# CTRL_MODULE_CORE register map
Vendor: Texas Instruments
Registers are 32-bit, access per field, reset 0x0 unless marked. A register's access mark holds for its fields unless they carry their own. Offsets are as the file gives them; [hi:lo] are bit positions; {n}, {i} and the like mark numbered series; 'fields as' and 'values as' point back to an identical list.

## CTRL_MODULE_CORE (part 4 of 12)
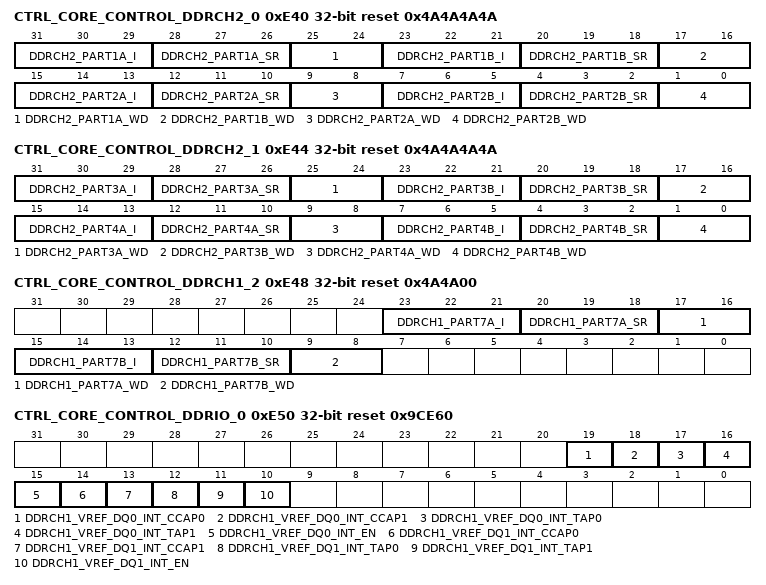
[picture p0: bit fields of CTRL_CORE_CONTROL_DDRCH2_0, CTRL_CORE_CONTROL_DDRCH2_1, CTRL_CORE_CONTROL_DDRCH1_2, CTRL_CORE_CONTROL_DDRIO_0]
0xE40 CTRL_CORE_CONTROL_DDRCH2_0 rw reset 0x4A4A4A4A — DDRCH2 control 0
  [31:29] DDRCH2_PART1A_I — PART1A Impedence control I[2:0] 0x0: Imp80 0x1: Imp60 0x2: Imp48 0x3: Imp40 0x4: Imp34 0x5: Reserved 0x6: Reserved 0x7: Reserved
  [28:26] DDRCH2_PART1A_SR — PART1A Slew Rate control SR[2:0]. All 8 values are valid. 0x0: Fastest .... 0x7: Slowest
  [25:24] DDRCH2_PART1A_WD — PART1A Weak driver control WD[1:0] -For single-ended operation: 0x0: Pull logic is disabled 0x1: Pull-up selected 0x2: Pull-down selected 0x3: Maintain the previous output value -For differential pair operation: 0x0: Pull logic is disabled 0x1: Pull-up selected for padp, pull-down selected for padn 0x2: Pull-down selected for padp, pull-up selected for padn 0x3: Maintain the previous output value
  [23:21] DDRCH2_PART1B_I — PART1B Impedence control I[2:0] 0x0: Imp80 0x1: Imp60 0x2: Imp48 0x3: Imp40 0x4: Imp34 0x5: Reserved 0x6: Reserved 0x7: Reserved
  [20:18] DDRCH2_PART1B_SR — PART1B Slew Rate control SR[2:0]. All 8 values are valid. 0x0: Fastest .... 0x7: Slowest
  [17:16] DDRCH2_PART1B_WD — PART1B Weak driver control WD[1:0] -For single-ended operation: 0x0: Pull logic is disabled 0x1: Pull-up selected 0x2: Pull-down selected 0x3: Maintain the previous output value -For differential pair operation: 0x0: Pull logic is disabled 0x1: Pull-up selected for padp, pull-down selected for padn 0x2: Pull-down selected for padp, pull-up selected for padn 0x3: Maintain the previous output value
  [15:13] DDRCH2_PART2A_I — PART2A Impedence control I[2:0] 0x0: Imp80 0x1: Imp60 0x2: Imp48 0x3: Imp40 0x4: Imp34 0x5: Reserved 0x6: Reserved 0x7: Reserved
  [12:10] DDRCH2_PART2A_SR — PART2A Slew Rate control SR[2:0]. All 8 values are valid. 0x0: Fastest .... 0x7: Slowest
  [9:8] DDRCH2_PART2A_WD — PART2A Weak driver control WD[1:0] -For single-ended operation: 0x0: Pull logic is disabled 0x1: Pull-up selected 0x2: Pull-down selected 0x3: Maintain the previous output value -For differential pair operation: 0x0: Pull logic is disabled 0x1: Pull-up selected for padp, pull-down selected for padn 0x2: Pull-down selected for padp, pull-up selected for padn 0x3: Maintain the previous output value
  [7:5] DDRCH2_PART2B_I — PART2B Impedence control I[2:0] 0x0: Imp80 0x1: Imp60 0x2: Imp48 0x3: Imp40 0x4: Imp34 0x5: Reserved 0x6: Reserved 0x7: Reserved
  [4:2] DDRCH2_PART2B_SR — PART2B Slew Rate control SR[2:0]. All 8 values are valid. 0x0: Fastest .... 0x7: Slowest
  [1:0] DDRCH2_PART2B_WD — PART2B Weak driver control WD[1:0] -For single-ended operation: 0x0: Pull logic is disabled 0x1: Pull-up selected 0x2: Pull-down selected 0x3: Maintain the previous output value -For differential pair operation: 0x0: Pull logic is disabled 0x1: Pull-up selected for padp, pull-down selected for padn 0x2: Pull-down selected for padp, pull-up selected for padn 0x3: Maintain the previous output value
0xE44 CTRL_CORE_CONTROL_DDRCH2_1 rw reset 0x4A4A4A4A — DDRCH2 control 1
  [31:29] DDRCH2_PART3A_I — PART3A Impedence control I[2:0] 0x0: Imp80 0x1: Imp60 0x2: Imp48 0x3: Imp40 0x4: Imp34 0x5: Reserved 0x6: Reserved 0x7: Reserved
  [28:26] DDRCH2_PART3A_SR — PART3A Slew Rate control SR[2:0]. All 8 values are valid. 0x0: Fastest .... 0x7: Slowest
  [25:24] DDRCH2_PART3A_WD — PART3A Weak driver control WD[1:0] -For single-ended operation: 0x0: Pull logic is disabled 0x1: Pull-up selected 0x2: Pull-down selected 0x3: Maintain the previous output value -For differential pair operation: 0x0: Pull logic is disabled 0x1: Pull-up selected for padp, pull-down selected for padn 0x2: Pull-down selected for padp, pull-up selected for padn 0x3: Maintain the previous output value
  [23:21] DDRCH2_PART3B_I — PART3B Impedence control I[2:0] 0x0: Imp80 0x1: Imp60 0x2: Imp48 0x3: Imp40 0x4: Imp34 0x5: Reserved 0x6: Reserved 0x7: Reserved
  [20:18] DDRCH2_PART3B_SR — PART3B Slew Rate control SR[2:0]. All 8 values are valid. 0x0: Fastest .... 0x7: Slowest
  [17:16] DDRCH2_PART3B_WD — PART3B Weak driver control WD[1:0] -For single-ended operation: 0x0: Pull logic is disabled 0x1: Pull-up selected 0x2: Pull-down selected 0x3: Maintain the previous output value -For differential pair operation: 0x0: Pull logic is disabled 0x1: Pull-up selected for padp, pull-down selected for padn 0x2: Pull-down selected for padp, pull-up selected for padn 0x3: Maintain the previous output value
  [15:13] DDRCH2_PART4A_I — PART4A Impedence control I[2:0] 0x0: Imp80 0x1: Imp60 0x2: Imp48 0x3: Imp40 0x4: Imp34 0x5: Reserved 0x6: Reserved 0x7: Reserved
  [12:10] DDRCH2_PART4A_SR — PART4A Slew Rate control SR[2:0]. All 8 values are valid. 0x0: Fastest .... 0x7: Slowest
  [9:8] DDRCH2_PART4A_WD — PART4A Weak driver control WD[1:0] -For single-ended operation: 0x0: Pull logic is disabled 0x1: Pull-up selected 0x2: Pull-down selected 0x3: Maintain the previous output value -For differential pair operation: 0x0: Pull logic is disabled 0x1: Pull-up selected for padp, pull-down selected for padn 0x2: Pull-down selected for padp, pull-up selected for padn 0x3: Maintain the previous output value
  [7:5] DDRCH2_PART4B_I — PART4B Impedence control I[2:0] 0x0: Imp80 0x1: Imp60 0x2: Imp48 0x3: Imp40 0x4: Imp34 0x5: Reserved 0x6: Reserved 0x7: Reserved
  [4:2] DDRCH2_PART4B_SR — PART4B Slew Rate control SR[2:0]. All 8 values are valid. 0x0: Fastest .... 0x7: Slowest
  [1:0] DDRCH2_PART4B_WD — PART4B Weak driver control WD[1:0] -For single-ended operation: 0x0: Pull logic is disabled 0x1: Pull-up selected 0x2: Pull-down selected 0x3: Maintain the previous output value -For differential pair operation: 0x0: Pull logic is disabled 0x1: Pull-up selected for padp, pull-down selected for padn 0x2: Pull-down selected for padp, pull-up selected for padn 0x3: Maintain the previous output value
0xE48 CTRL_CORE_CONTROL_DDRCH1_2 reset 0x4A4A00
  [23:21] DDRCH1_PART7A_I rw — PART7A Impedence control I[2:0] 0x0: Imp80 0x1: Imp60 0x2: Imp48 0x3: Imp40 0x4: Imp34 0x5: Reserved 0x6: Reserved 0x7: Reserved
  [20:18] DDRCH1_PART7A_SR rw — PART7A Slew Rate control SR[2:0]. All 8 values are valid. 0x0: Fastest .... 0x7: Slowest
  [17:16] DDRCH1_PART7A_WD rw — PART7A Weak driver control WD[1:0] -For single-ended operation: 0x0: Pull logic is disabled 0x1: Pull-up selected 0x2: Pull-down selected 0x3: Maintain the previous output value -For differential pair operation: 0x0: Pull logic is disabled 0x1: Pull-up selected for padp, pull-down selected for padn 0x2: Pull-down selected for padp, pull-up selected for padn 0x3: Maintain the previous output value
  [15:13] DDRCH1_PART7B_I rw — PART7B Impedence control I[2:0] 0x0: Imp80 0x1: Imp60 0x2: Imp48 0x3: Imp40 0x4: Imp34 0x5: Reserved 0x6: Reserved 0x7: Reserved
  [12:10] DDRCH1_PART7B_SR rw — PART7B Slew Rate control SR[2:0]. All 8 values are valid. 0x0: Fastest .... 0x7: Slowest
  [9:8] DDRCH1_PART7B_WD rw — PART7B Weak driver control WD[1:0] -For single-ended operation: 0x0: Pull logic is disabled 0x1: Pull-up selected 0x2: Pull-down selected 0x3: Maintain the previous output value -For differential pair operation: 0x0: Pull logic is disabled 0x1: Pull-up selected for padp, pull-down selected for padn 0x2: Pull-down selected for padp, pull-up selected for padn 0x3: Maintain the previous output value
0xE50 CTRL_CORE_CONTROL_DDRIO_0 reset 0x9CE60
  [all] fields
    0=DISABLE (Disabled); 1=ENABLE (Enabled)
  [19] DDRCH1_VREF_DQ0_INT_CCAP0 rw — Selection for coupling cap connection
  [18] DDRCH1_VREF_DQ0_INT_CCAP1 rw — Selection for coupling cap connection
  [17] DDRCH1_VREF_DQ0_INT_TAP0 rw — Selection for internal reference voltage drive
  [16] DDRCH1_VREF_DQ0_INT_TAP1 rw — Selection for internal reference voltage drive
  [15] DDRCH1_VREF_DQ0_INT_EN rw — Enable
  [14] DDRCH1_VREF_DQ1_INT_CCAP0 rw — Selection for coupling cap connection
  [13] DDRCH1_VREF_DQ1_INT_CCAP1 rw — Selection for coupling cap connection
  [12] DDRCH1_VREF_DQ1_INT_TAP0 rw — Selection for internal reference voltage drive
  [11] DDRCH1_VREF_DQ1_INT_TAP1 rw — Selection for internal reference voltage drive
  [10] DDRCH1_VREF_DQ1_INT_EN rw — Enable
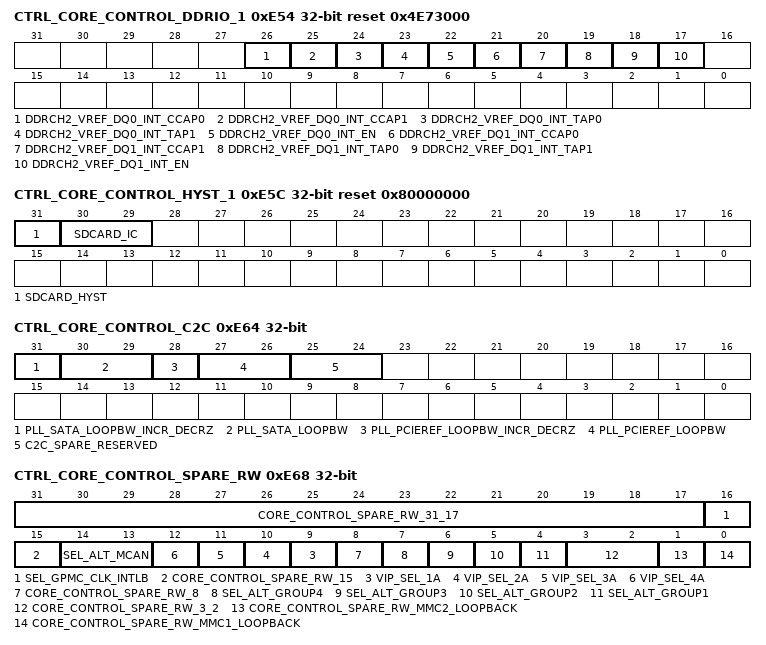
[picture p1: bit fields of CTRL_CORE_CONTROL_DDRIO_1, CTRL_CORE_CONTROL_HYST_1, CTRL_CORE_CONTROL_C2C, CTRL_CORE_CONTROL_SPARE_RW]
0xE54 CTRL_CORE_CONTROL_DDRIO_1 reset 0x4E73000
  [all] fields
    0=DISABLE (Disabled); 1=ENABLE (Enabled)
  [26] DDRCH2_VREF_DQ0_INT_CCAP0 rw — Selection for coupling cap connection
  [25] DDRCH2_VREF_DQ0_INT_CCAP1 rw — Selection for coupling cap connection
  [24] DDRCH2_VREF_DQ0_INT_TAP0 rw — Selection for internal reference voltage drive
  [23] DDRCH2_VREF_DQ0_INT_TAP1 rw — Selection for internal reference voltage drive
  [22] DDRCH2_VREF_DQ0_INT_EN rw — Enable
  [21] DDRCH2_VREF_DQ1_INT_CCAP0 rw — Selection for coupling cap connection
  [20] DDRCH2_VREF_DQ1_INT_CCAP1 rw — Selection for coupling cap connection
  [19] DDRCH2_VREF_DQ1_INT_TAP0 rw — Selection for internal reference voltage drive
  [18] DDRCH2_VREF_DQ1_INT_TAP1 rw — Selection for internal reference voltage drive
  [17] DDRCH2_VREF_DQ1_INT_EN rw — Enable
0xE5C CTRL_CORE_CONTROL_HYST_1 reset 0x80000000 — Register for hysteresis and impedance control of the MMC1 pads. Effective when corresponding MUXMODE field is not configured for MMC operation.
  [31] SDCARD_HYST rw — Hysteresis control for sdcard 0x0 = Disabled 0x1 = Enabled
  [30:29] SDCARD_IC rw — Drive strength control for MMC1 pads In 3.3V signaling mode: 0x0: 50 Ohms Drive Strength 0x1: 33 Ohms Drive Strength 0x2: 66 Ohms Drive Strength 0x3: Reserved In 1.8V signaling mode: 0x0: 44 Ohms Drive Strength 0x1: 33 Ohms Drive Strength 0x2: 58 Ohms Drive Strength 0x3: 100 Ohms Drive Strength
0xE64 CTRL_CORE_CONTROL_C2C — Loop Bandwidth control for DPLL_SATA and DPLL_PCIE_REF.
  [31] PLL_SATA_LOOPBW_INCR_DECRZ rw — 0x0: Decrease DPLL_SATA loop bandwidth 0x1: Increase DPLL_SATA loop bandwidth
  [30:29] PLL_SATA_LOOPBW rw — DPLL_SATA loop bandwidth mode If PLL_SATA_LOOPBW_INCR_DECRZ = 0x0: 0x0: 1x Mode (Loop BW is REF_CLK/50) 0x1: 0.5x Mode (Loop BW is REF_CLK/100) 0x2: 0.25x Mode (Loop BW is REF_CLK/200) 0x3: 0.125x Mode (Loop BW is REF_CLK/400) If PLL_SATA_LOOPBW_INCR_DECRZ = 0x1: 0x0: 1x Mode (Loop BW is REF_CLK/50) 0x1: 2x Mode (Loop BW is REF_CLK/25) 0x2: Reserved 0x3: Reserved
  [28] PLL_PCIEREF_LOOPBW_INCR_DECRZ rw — 0x0: Decrease DPLL_PCIE_REF loop bandwidth 0x1: Increase DPLL_PCIE_REF loop bandwidth
  [27:26] PLL_PCIEREF_LOOPBW rw — DPLL_PCIE_REF loop bandwidth mode If PLL_PCIEREF_LOOPBW_INCR_DECRZ = 0x0: 0x0: 1x Mode (Loop BW is REF_CLK/50) 0x1: 0.5x Mode (Loop BW is REF_CLK/100) 0x2: 0.25x Mode (Loop BW is REF_CLK/200) 0x3: 0.125x Mode (Loop BW is REF_CLK/400) If PLL_PCIEREF_LOOPBW_INCR_DECRZ = 0x1: 0x0: 1x Mode (Loop BW is REF_CLK/50) 0x1: 2x Mode (Loop BW is REF_CLK/25) 0x2: Reserved 0x3: Reserved
  [25:24] C2C_SPARE_RESERVED rw — Reserved bits
0xE68 CTRL_CORE_CONTROL_SPARE_RW rw
  [31:17] CORE_CONTROL_SPARE_RW_31_17 — Spare bits
  [16] SEL_GPMC_CLK_INTLB — Selects the source of loopback clock for gpmc_clk. 0x0: Loopback clock from the I/O pad is selected 0x1: Internal loopback clock is selected
  [15] CORE_CONTROL_SPARE_RW_15 — Spare bits
  [14:13] SEL_ALT_MCAN — Selection for MCAN signal muxing 0x0: The dcan2_tx and dcan2_rx signals are on the gpio6_14 and gpio6_15 pads when MUXMODE = 0x2 or the dcan1_tx and dcan1_rx signals are on the dcan1_tx and dcan1_rx pads when MUXMODE = 0x0. 0x1: The mcan_tx and mcan_rx signals are on the dcan1_tx and dcan1_rx pads when MUXMODE = 0x0. 0x2: The mcan_tx and mcan_rx signals are on the gpio6_14 and gpio6_15 pads when MUXMODE = 0x2. 0x3: Reserved
  [n+8] VIP_SEL_{n}A (n=1..4) — 0x0: Input for vin{n}a comes from device vin{n}a pads 0x1: Input for vin{n}a comes from CAL video port {n} signals
  [8] CORE_CONTROL_SPARE_RW_8 — Spare bit
  [7] SEL_ALT_GROUP4 — Selects a signal as described in
  [6] SEL_ALT_GROUP3 — 0x0: GPIO function is selected on the pads from GROUP3 0x1: New function is selected on the pads from GROUP3 as described in
  [5] SEL_ALT_GROUP2 — Selects a signal as described in
  [4] SEL_ALT_GROUP1 — 0x0: GPIO function is selected on the pads from GROUP1 0x1: New function is selected on the pads from GROUP1 as described in
  [3:2] CORE_CONTROL_SPARE_RW_3_2 — Spare bits
  [1] CORE_CONTROL_SPARE_RW_MMC2_LOOPBACK — Selects the source of loopback clock for mmc2_clk. 0x0: Loopback clock from the I/O pad is selected 0x1: Internal loopback clock is selected
  [0] CORE_CONTROL_SPARE_RW_MMC1_LOOPBACK — Selects the source of loopback clock for mmc1_clk. 0x0: Loopback clock from the I/O pad is selected 0x1: Internal loopback clock is selected
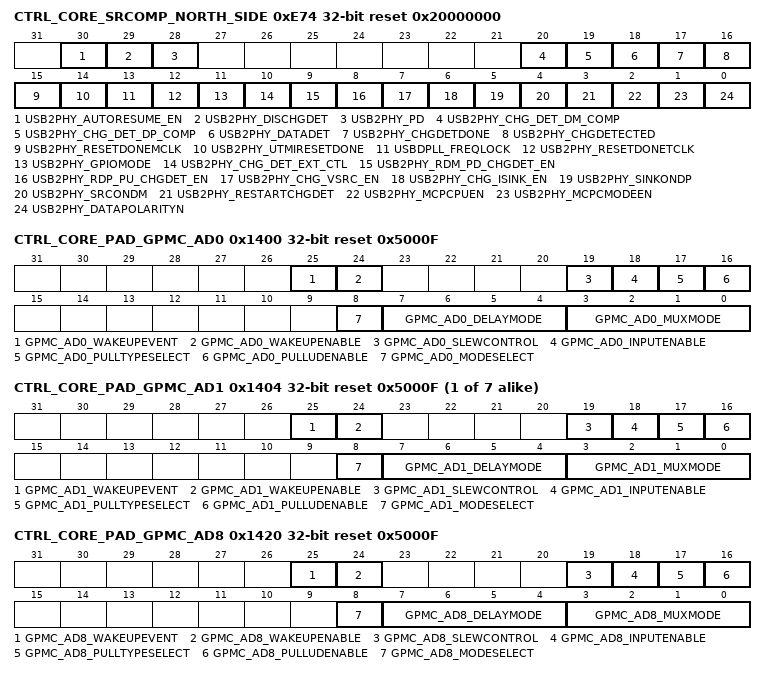
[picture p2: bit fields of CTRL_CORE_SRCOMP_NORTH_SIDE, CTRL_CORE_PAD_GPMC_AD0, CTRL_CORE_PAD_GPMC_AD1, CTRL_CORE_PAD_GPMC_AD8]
0xE74 CTRL_CORE_SRCOMP_NORTH_SIDE reset 0x20000000 — This register is related to the USB2_PHY2.
  [30] USB2PHY_AUTORESUME_EN rw — Auto resume enable 0x0: disable autoresume 0x1: enable autoresume
  [29] USB2PHY_DISCHGDET rw — Disable charger detect 0x0: charger detect function enabled 0x1: charger detect function disabled
  [28] USB2PHY_PD rw — Power down the entire USB2_PHY2 (data, common module and UTMI). 0x0: Normal operation 0x1: Power down the USB2_PHY2
  [20] USB2PHY_CHG_DET_DM_COMP ro — Output of the comparator on DM during the resistor host detect protocol 0x0: DM line is below 0.75V to 0.95V 0x1: DM line is above 0.75V to 0.95V
  [19] USB2PHY_CHG_DET_DP_COMP ro — Output of the comparator on DP during the resistor host detect protocol 0x0: DP line is below 0.75V to 0.95V 0x1: DP line is above 0.75V to 0.95V
  [18] USB2PHY_DATADET ro — Output of the charger detect comparator 0x0: DM line is below 0.25V to 0.4V 0x1: DM line is above 0.25V to 0.4V
  [17] USB2PHY_CHGDETDONE ro — Status indicates that charger detection protocol is over 0x0: charger detection protocol is not over 0x1: charger detection protocol is over
  [16] USB2PHY_CHGDETECTED ro — Output of the charger detection protocol 0x0: charger not detected 0x1: charger detected
  [15] USB2PHY_RESETDONEMCLK ro — OCP reset status 0x0: OCP domain is in reset 0x1: OCP domain is out of reset
  [14] USB2PHY_UTMIRESETDONE ro — UTMI FSM reset status 0x0: UTMI FSMs are in reset 0x1: UTMI FSMs are out of reset
  [13] USBDPLL_FREQLOCK ro — Status from USB DPLL
  [12] USB2PHY_RESETDONETCLK ro — resetdonetclk status from USB2_PHY2
  [11] USB2PHY_GPIOMODE rw — GPIO mode 0x0: USB mode enabled 0x1: GPIO mode enabled
  [10] USB2PHY_CHG_DET_EXT_CTL rw — Charge detect external control 0x0: charger detect internal state machine used 0x1: charge detect statemachine is bypassed
  [9] USB2PHY_RDM_PD_CHGDET_EN rw — DM Pull down control 0x0: PD disabled 0x1: PD enabled
  [8] USB2PHY_RDP_PU_CHGDET_EN rw — DP Pull up control 0x0: PU disabled 0x1: PU enabled
  [7] USB2PHY_CHG_VSRC_EN rw — VSRC enable on DP line: Host charger case 0x0: disable VSRC drive on DP 0x1: drives VSRC 600mV on DP line
  [6] USB2PHY_CHG_ISINK_EN rw — ISINK enable on DM line: Host charger case 0x0: disable the ISINK on DM 0x1: enables the ISINK (100uA) on DM line
  [5] USB2PHY_SINKONDP rw — When '1' current sink is connected to DP instead of DM 0x0: Default value 0x1: enables the ISINK on DP instead of DM
  [4] USB2PHY_SRCONDM rw — When '1' voltage source is connected to DP instead of DM 0x0: Default value 0x1: enable the VSRC on DM instead of DP
  [3] USB2PHY_RESTARTCHGDET rw — restartchgdet: '1' for 1 msec cause the CD_START to reset 0x0: Default value 0x1: a high pulse of 1 msec causes the charger detect to restart on negative edge of restartchgdet
  [2] USB2PHY_MCPCPUEN rw — MCPC Pull up enable 0x0: disable the MCPC pull up 0x1: enable the 4.7K to10K pull up on receive line DP when datapolarityn is 0 and DM when datapolarityn is 1
  [1] USB2PHY_MCPCMODEEN rw — MCPC Mode enable 0x0: disable MCPC mode 0x1: enable MCPC mode
  [0] USB2PHY_DATAPOLARITYN rw — Data polarity 0x0: DP functionality is on DP and DM funcationality is on DM 0x1: DP functionality is on DM and DM functionality is on DP
0xE78 CTRL_CORE_SRCOMP_SOUTH_SIDE ro — This register is related to the USB2_PHY2.
  [14:12] USB2PHY_CHG_DET_STATUS — Status of charger detection 0x0: Wait state 0x1: No contact 0x2: PS/2 0x3: Unknown error 0x4: Dedicated charger 0x5: HOST charger 0x6: PC 0x7: Interrupt
0x1400 CTRL_CORE_PAD_GPMC_AD0 reset 0x5000F
  [25] GPMC_AD0_WAKEUPEVENT ro
    0=NOWAKEUP (No wakeup event detected); 1=WAKEUP (Wakeup event detected)
  [24] GPMC_AD0_WAKEUPENABLE rw
    0=DISABLE (Wakeup is disabled); 1=ENABLE (Wakeup is enabled)
  [19] GPMC_AD0_SLEWCONTROL rw
    0=FAST_SLEW (Fast slew is selected); 1=SLOW_SLEW (Slow slew is selected)
  [18] GPMC_AD0_INPUTENABLE rw
    0=DISABLE (Receive mode is disabled); 1=ENABLE (Receive mode is enabled)
  [17] GPMC_AD0_PULLTYPESELECT rw
    0=PULL_DOWN (Pull Down is selected); 1=PULL_UP (Pull Up is selected)
  [16] GPMC_AD0_PULLUDENABLE rw
    0=ENABLE (Enables weak Pull Up/Down); 1=DISABLE (Disables weak Pull Up/Down)
  [8] GPMC_AD0_MODESELECT rw — Selects between the Default IO Timing Mode and a Virtual or Manual IO Timing Mode.Refer to the device Data Manual for definition of the required settings for a given mode of operation. When this bit is 0b1, a Virtual IO Timing Mode can be selected via the DELAYMODE field of this register, as described in , Virtual IO Timing Modes. Manual IO Timing Modes are selected via the procedure described in , Manual IO Timing Modes.
    0=MUX_MODE (Default IO Timing Mode is used); 1=DELAY_MODE (A Virtual or Manual IO Timing Mode is used)
  [7:4] GPMC_AD0_DELAYMODE rw — This bit field selects the Virtual Timing Mode used when the MODESELECT bit is set to 0b1. See, Virtual IO Timing Modes for details.
  [3:0] GPMC_AD0_MUXMODE rw
    0=GPMC_AD0; 2=VIN3A_D0; 3=VOUT3_D0; 14=GPIO1_6; 15=SYSBOOT0
{0x1400+4i} CTRL_CORE_PAD_GPMC_AD{i} reset 0x5000F (i=1..7)
  [25] GPMC_AD{i}_WAKEUPEVENT ro
    values as CTRL_CORE_PAD_GPMC_AD0.GPMC_AD0_WAKEUPEVENT
  [24] GPMC_AD{i}_WAKEUPENABLE rw
    0=DISABLE (Wakeup is disabled); 1=ENABLE (Wakeup is enabled)
  [19] GPMC_AD{i}_SLEWCONTROL rw
    values as CTRL_CORE_PAD_GPMC_AD0.GPMC_AD0_SLEWCONTROL
  [18] GPMC_AD{i}_INPUTENABLE rw
    values as CTRL_CORE_PAD_GPMC_AD0.GPMC_AD0_INPUTENABLE
  [17] GPMC_AD{i}_PULLTYPESELECT rw
    values as CTRL_CORE_PAD_GPMC_AD0.GPMC_AD0_PULLTYPESELECT
  [16] GPMC_AD{i}_PULLUDENABLE rw
    values as CTRL_CORE_PAD_GPMC_AD0.GPMC_AD0_PULLUDENABLE
  [8] GPMC_AD{i}_MODESELECT rw — Selects between the Default IO Timing Mode and a Virtual or Manual IO Timing Mode. Refer to the device Data Manual for definition of the required settings for a given mode of operation. When this bit is 0b1, a Virtual IO Timing Mode can be selected via the DELAYMODE field of this register, as described in, Virtual IO Timing Modes. Manual IO Timing Modes are selected via the procedure described in , Manual IO Timing Modes.
    values as CTRL_CORE_PAD_GPMC_AD0.GPMC_AD0_MODESELECT
  [7:4] GPMC_AD{i}_DELAYMODE rw — This bit field selects the Virtual Timing Mode used when the MODESELECT bit is set to 0b1. See, Virtual IO Timing Modes for details.
  [3:0] GPMC_AD{i}_MUXMODE rw
    0=GPMC_AD{i}; 2=VIN3A_D{i}; 3=VOUT3_D{i}; 14=GPIO1_{i+6}; 15=SYSBOOT{i}
0x1420 CTRL_CORE_PAD_GPMC_AD8 reset 0x5000F
  [25] GPMC_AD8_WAKEUPEVENT ro
    values as CTRL_CORE_PAD_GPMC_AD0.GPMC_AD0_WAKEUPEVENT
  [24] GPMC_AD8_WAKEUPENABLE rw
    0=DISABLE (Wakeup is disabled); 1=ENABLE (Wakeup is enabled)
  [19] GPMC_AD8_SLEWCONTROL rw
    values as CTRL_CORE_PAD_GPMC_AD0.GPMC_AD0_SLEWCONTROL
  [18] GPMC_AD8_INPUTENABLE rw
    values as CTRL_CORE_PAD_GPMC_AD0.GPMC_AD0_INPUTENABLE
  [17] GPMC_AD8_PULLTYPESELECT rw
    values as CTRL_CORE_PAD_GPMC_AD0.GPMC_AD0_PULLTYPESELECT
  [16] GPMC_AD8_PULLUDENABLE rw
    values as CTRL_CORE_PAD_GPMC_AD0.GPMC_AD0_PULLUDENABLE
  [8] GPMC_AD8_MODESELECT rw — Selects between the Default IO Timing Mode and a Virtual or Manual IO Timing Mode. Refer to the device Data Manual for definition of the required settings for a given mode of operation. When this bit is 0b1, a Virtual IO Timing Mode can be selected via the DELAYMODE field of this register, as described in, Virtual IO Timing Modes. Manual IO Timing Modes are selected via the procedure described in , Manual IO Timing Modes.
    values as CTRL_CORE_PAD_GPMC_AD0.GPMC_AD0_MODESELECT
  [7:4] GPMC_AD8_DELAYMODE rw — This bit field selects the Virtual Timing Mode used when the MODESELECT bit is set to 0b1. See, Virtual IO Timing Modes for details.
  [3:0] GPMC_AD8_MUXMODE rw
    0=GPMC_AD8; 2=VIN3A_D8; 3=VOUT3_D8; 14=GPIO7_18; 15=SYSBOOT8
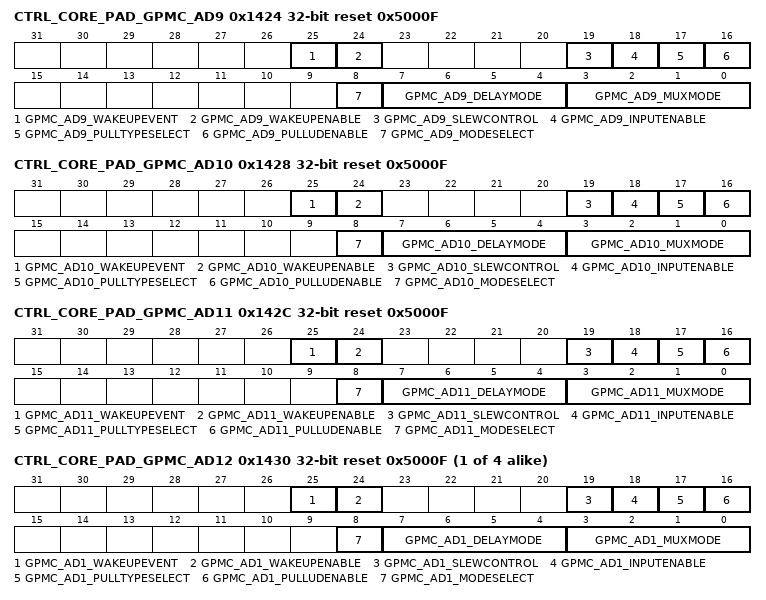
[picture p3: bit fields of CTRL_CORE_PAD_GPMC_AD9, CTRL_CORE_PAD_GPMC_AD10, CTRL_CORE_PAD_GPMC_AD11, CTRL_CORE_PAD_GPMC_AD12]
0x1424 CTRL_CORE_PAD_GPMC_AD9 reset 0x5000F
  [25] GPMC_AD9_WAKEUPEVENT ro
    values as CTRL_CORE_PAD_GPMC_AD0.GPMC_AD0_WAKEUPEVENT
  [24] GPMC_AD9_WAKEUPENABLE rw
    0=DISABLE (Wakeup is disabled); 1=ENABLE (Wakeup is enabled)
  [19] GPMC_AD9_SLEWCONTROL rw
    values as CTRL_CORE_PAD_GPMC_AD0.GPMC_AD0_SLEWCONTROL
  [18] GPMC_AD9_INPUTENABLE rw
    values as CTRL_CORE_PAD_GPMC_AD0.GPMC_AD0_INPUTENABLE
  [17] GPMC_AD9_PULLTYPESELECT rw
    values as CTRL_CORE_PAD_GPMC_AD0.GPMC_AD0_PULLTYPESELECT
  [16] GPMC_AD9_PULLUDENABLE rw
    values as CTRL_CORE_PAD_GPMC_AD0.GPMC_AD0_PULLUDENABLE
  [8] GPMC_AD9_MODESELECT rw — Selects between the Default IO Timing Mode and a Virtual or Manual IO Timing Mode. Refer to the device Data Manual for definition of the required settings for a given mode of operation. When this bit is 0b1, a Virtual IO Timing Mode can be selected via the DELAYMODE field of this register, as described in, Virtual IO Timing Modes. Manual IO Timing Modes are selected via the procedure described in , Manual IO Timing Modes.
    values as CTRL_CORE_PAD_GPMC_AD0.GPMC_AD0_MODESELECT
  [7:4] GPMC_AD9_DELAYMODE rw — This bit field selects the Virtual Timing Mode used when the MODESELECT bit is set to 0b1. See, Virtual IO Timing Modes for details.
  [3:0] GPMC_AD9_MUXMODE rw
    0=GPMC_AD9; 2=VIN3A_D9; 3=VOUT3_D9; 14=GPIO7_19; 15=SYSBOOT9
0x1428 CTRL_CORE_PAD_GPMC_AD10 reset 0x5000F
  [25] GPMC_AD10_WAKEUPEVENT ro
    values as CTRL_CORE_PAD_GPMC_AD0.GPMC_AD0_WAKEUPEVENT
  [24] GPMC_AD10_WAKEUPENABLE rw
    0=DISABLE (Wakeup is disabled); 1=ENABLE (Wakeup is enabled)
  [19] GPMC_AD10_SLEWCONTROL rw
    values as CTRL_CORE_PAD_GPMC_AD0.GPMC_AD0_SLEWCONTROL
  [18] GPMC_AD10_INPUTENABLE rw
    values as CTRL_CORE_PAD_GPMC_AD0.GPMC_AD0_INPUTENABLE
  [17] GPMC_AD10_PULLTYPESELECT rw
    values as CTRL_CORE_PAD_GPMC_AD0.GPMC_AD0_PULLTYPESELECT
  [16] GPMC_AD10_PULLUDENABLE rw
    values as CTRL_CORE_PAD_GPMC_AD0.GPMC_AD0_PULLUDENABLE
  [8] GPMC_AD10_MODESELECT rw — Selects between the Default IO Timing Mode and a Virtual or Manual IO Timing Mode. Refer to the device Data Manual for definition of the required settings for a given mode of operation. When this bit is 0b1, a Virtual IO Timing Mode can be selected via the DELAYMODE field of this register, as described in, Virtual IO Timing Modes. Manual IO Timing Modes are selected via the procedure described in , Manual IO Timing Modes.
    values as CTRL_CORE_PAD_GPMC_AD0.GPMC_AD0_MODESELECT
  [7:4] GPMC_AD10_DELAYMODE rw — This bit field selects the Virtual Timing Mode used when the MODESELECT bit is set to 0b1. See, Virtual IO Timing Modes for details.
  [3:0] GPMC_AD10_MUXMODE rw
    0=GPMC_AD10; 2=VIN3A_D10; 3=VOUT3_D10; 14=GPIO7_28; 15=SYSBOOT10
0x142C CTRL_CORE_PAD_GPMC_AD11 reset 0x5000F
  [25] GPMC_AD11_WAKEUPEVENT ro
    values as CTRL_CORE_PAD_GPMC_AD0.GPMC_AD0_WAKEUPEVENT
  [24] GPMC_AD11_WAKEUPENABLE rw
    0=DISABLE (Wakeup is disabled); 1=ENABLE (Wakeup is enabled)
  [19] GPMC_AD11_SLEWCONTROL rw
    values as CTRL_CORE_PAD_GPMC_AD0.GPMC_AD0_SLEWCONTROL
  [18] GPMC_AD11_INPUTENABLE rw
    values as CTRL_CORE_PAD_GPMC_AD0.GPMC_AD0_INPUTENABLE
  [17] GPMC_AD11_PULLTYPESELECT rw
    values as CTRL_CORE_PAD_GPMC_AD0.GPMC_AD0_PULLTYPESELECT
  [16] GPMC_AD11_PULLUDENABLE rw
    values as CTRL_CORE_PAD_GPMC_AD0.GPMC_AD0_PULLUDENABLE
  [8] GPMC_AD11_MODESELECT rw — Selects between the Default IO Timing Mode and a Virtual or Manual IO Timing Mode. Refer to the device Data Manual for definition of the required settings for a given mode of operation. When this bit is 0b1, a Virtual IO Timing Mode can be selected via the DELAYMODE field of this register, as described in, Virtual IO Timing Modes. Manual IO Timing Modes are selected via the procedure described in , Manual IO Timing Modes.
    values as CTRL_CORE_PAD_GPMC_AD0.GPMC_AD0_MODESELECT
  [7:4] GPMC_AD11_DELAYMODE rw — This bit field selects the Virtual Timing Mode used when the MODESELECT bit is set to 0b1. See, Virtual IO Timing Modes for details.
  [3:0] GPMC_AD11_MUXMODE rw
    0=GPMC_AD11; 2=VIN3A_D11; 3=VOUT3_D11; 14=GPIO7_29; 15=SYSBOOT11
{0x1400+4i} CTRL_CORE_PAD_GPMC_AD{i} reset 0x5000F (i=12..15)
  fields as CTRL_CORE_PAD_GPMC_AD1
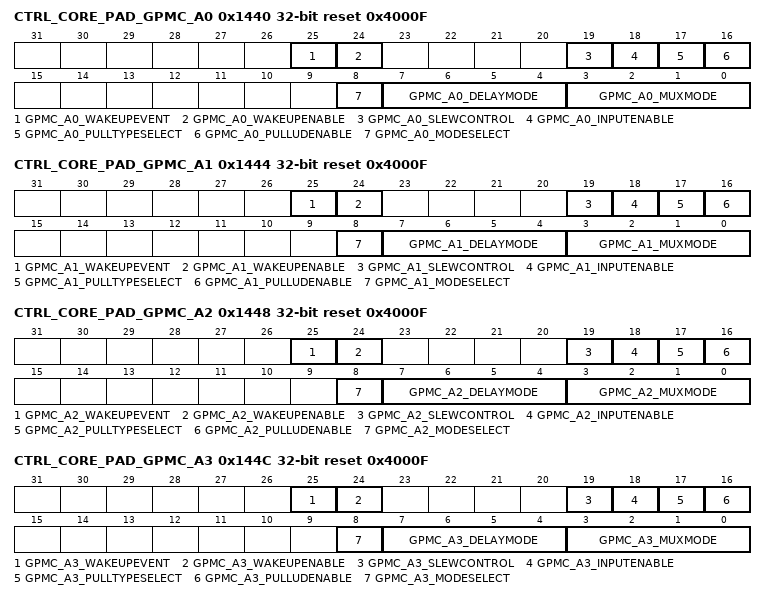
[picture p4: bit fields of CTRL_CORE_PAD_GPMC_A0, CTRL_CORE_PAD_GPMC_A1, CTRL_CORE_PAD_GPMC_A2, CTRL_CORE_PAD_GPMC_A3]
0x1440 CTRL_CORE_PAD_GPMC_A0 reset 0x4000F
  [25] GPMC_A0_WAKEUPEVENT ro
    values as CTRL_CORE_PAD_GPMC_AD0.GPMC_AD0_WAKEUPEVENT
  [24] GPMC_A0_WAKEUPENABLE rw
    0=DISABLE (Wakeup is disabled); 1=ENABLE (Wakeup is enabled)
  [19] GPMC_A0_SLEWCONTROL rw
    values as CTRL_CORE_PAD_GPMC_AD0.GPMC_AD0_SLEWCONTROL
  [18] GPMC_A0_INPUTENABLE rw
    values as CTRL_CORE_PAD_GPMC_AD0.GPMC_AD0_INPUTENABLE
  [17] GPMC_A0_PULLTYPESELECT rw
    values as CTRL_CORE_PAD_GPMC_AD0.GPMC_AD0_PULLTYPESELECT
  [16] GPMC_A0_PULLUDENABLE rw
    values as CTRL_CORE_PAD_GPMC_AD0.GPMC_AD0_PULLUDENABLE
  [8] GPMC_A0_MODESELECT rw — Selects between the Default IO Timing Mode and a Virtual or Manual IO Timing Mode. Refer to the device Data Manual for definition of the required settings for a given mode of operation. When this bit is 0b1, a Virtual IO Timing Mode can be selected via the DELAYMODE field of this register, as described in, Virtual IO Timing Modes. Manual IO Timing Modes are selected via the procedure described in , Manual IO Timing Modes.
    values as CTRL_CORE_PAD_GPMC_AD0.GPMC_AD0_MODESELECT
  [7:4] GPMC_A0_DELAYMODE rw — This bit field selects the Virtual Timing Mode used when the MODESELECT bit is set to 0b1. See, Virtual IO Timing Modes for details.
  [3:0] GPMC_A0_MUXMODE rw
    0=GPMC_A0; 2=VIN3A_D16; 3=VOUT3_D16; 4=VIN4A_D0; 6=VIN4B_D0; 7=I2C4_SCL; 8=UART5_RXD; 14=GPIO7_3; 15=DRIVER OFF
0x1444 CTRL_CORE_PAD_GPMC_A1 reset 0x4000F
  [25] GPMC_A1_WAKEUPEVENT ro
    values as CTRL_CORE_PAD_GPMC_AD0.GPMC_AD0_WAKEUPEVENT
  [24] GPMC_A1_WAKEUPENABLE rw
    0=DISABLE (Wakeup is disabled); 1=ENABLE (Wakeup is enabled)
  [19] GPMC_A1_SLEWCONTROL rw
    values as CTRL_CORE_PAD_GPMC_AD0.GPMC_AD0_SLEWCONTROL
  [18] GPMC_A1_INPUTENABLE rw
    values as CTRL_CORE_PAD_GPMC_AD0.GPMC_AD0_INPUTENABLE
  [17] GPMC_A1_PULLTYPESELECT rw
    values as CTRL_CORE_PAD_GPMC_AD0.GPMC_AD0_PULLTYPESELECT
  [16] GPMC_A1_PULLUDENABLE rw
    values as CTRL_CORE_PAD_GPMC_AD0.GPMC_AD0_PULLUDENABLE
  [8] GPMC_A1_MODESELECT rw — Selects between the Default IO Timing Mode and a Virtual or Manual IO Timing Mode. Refer to the device Data Manual for definition of the required settings for a given mode of operation. When this bit is 0b1, a Virtual IO Timing Mode can be selected via the DELAYMODE field of this register, as described in, Virtual IO Timing Modes. Manual IO Timing Modes are selected via the procedure described in , Manual IO Timing Modes.
    values as CTRL_CORE_PAD_GPMC_AD0.GPMC_AD0_MODESELECT
  [7:4] GPMC_A1_DELAYMODE rw — This bit field selects the Virtual Timing Mode used when the MODESELECT bit is set to 0b1. See, Virtual IO Timing Modes for details.
  [3:0] GPMC_A1_MUXMODE rw
    0=GPMC_A1; 2=VIN3A_D17; 3=VOUT3_D17; 4=VIN4A_D1; 6=VIN4B_D1; 7=I2C4_SDA; 8=UART5_TXD; 14=GPIO7_4; 15=DRIVER OFF
0x1448 CTRL_CORE_PAD_GPMC_A2 reset 0x4000F
  [25] GPMC_A2_WAKEUPEVENT ro
    values as CTRL_CORE_PAD_GPMC_AD0.GPMC_AD0_WAKEUPEVENT
  [24] GPMC_A2_WAKEUPENABLE rw
    0=DISABLE (Wakeup is disabled); 1=ENABLE (Wakeup is enabled)
  [19] GPMC_A2_SLEWCONTROL rw
    values as CTRL_CORE_PAD_GPMC_AD0.GPMC_AD0_SLEWCONTROL
  [18] GPMC_A2_INPUTENABLE rw
    values as CTRL_CORE_PAD_GPMC_AD0.GPMC_AD0_INPUTENABLE
  [17] GPMC_A2_PULLTYPESELECT rw
    values as CTRL_CORE_PAD_GPMC_AD0.GPMC_AD0_PULLTYPESELECT
  [16] GPMC_A2_PULLUDENABLE rw
    values as CTRL_CORE_PAD_GPMC_AD0.GPMC_AD0_PULLUDENABLE
  [8] GPMC_A2_MODESELECT rw — Selects between the Default IO Timing Mode and a Virtual or Manual IO Timing Mode. Refer to the device Data Manual for definition of the required settings for a given mode of operation. When this bit is 0b1, a Virtual IO Timing Mode can be selected via the DELAYMODE field of this register, as described in, Virtual IO Timing Modes. Manual IO Timing Modes are selected via the procedure described in , Manual IO Timing Modes.
    values as CTRL_CORE_PAD_GPMC_AD0.GPMC_AD0_MODESELECT
  [7:4] GPMC_A2_DELAYMODE rw — This bit field selects the Virtual Timing Mode used when the MODESELECT bit is set to 0b1. See, Virtual IO Timing Modes for details.
  [3:0] GPMC_A2_MUXMODE rw
    0=GPMC_A2; 2=VIN3A_D18; 3=VOUT3_D18; 4=VIN4A_D2; 6=VIN4B_D2; 7=UART7_RXD; 8=UART5_CTSN; 14=GPIO7_5; 15=DRIVER OFF
0x144C CTRL_CORE_PAD_GPMC_A3 reset 0x4000F
  [25] GPMC_A3_WAKEUPEVENT ro
    values as CTRL_CORE_PAD_GPMC_AD0.GPMC_AD0_WAKEUPEVENT
  [24] GPMC_A3_WAKEUPENABLE rw
    0=DISABLE (Wakeup is disabled); 1=ENABLE (Wakeup is enabled)
  [19] GPMC_A3_SLEWCONTROL rw
    values as CTRL_CORE_PAD_GPMC_AD0.GPMC_AD0_SLEWCONTROL
  [18] GPMC_A3_INPUTENABLE rw
    values as CTRL_CORE_PAD_GPMC_AD0.GPMC_AD0_INPUTENABLE
  [17] GPMC_A3_PULLTYPESELECT rw
    values as CTRL_CORE_PAD_GPMC_AD0.GPMC_AD0_PULLTYPESELECT
  [16] GPMC_A3_PULLUDENABLE rw
    values as CTRL_CORE_PAD_GPMC_AD0.GPMC_AD0_PULLUDENABLE
  [8] GPMC_A3_MODESELECT rw — Selects between the Default IO Timing Mode and a Virtual or Manual IO Timing Mode. Refer to the device Data Manual for definition of the required settings for a given mode of operation. When this bit is 0b1, a Virtual IO Timing Mode can be selected via the DELAYMODE field of this register, as described in, Virtual IO Timing Modes. Manual IO Timing Modes are selected via the procedure described in , Manual IO Timing Modes.
    values as CTRL_CORE_PAD_GPMC_AD0.GPMC_AD0_MODESELECT
  [7:4] GPMC_A3_DELAYMODE rw — This bit field selects the Virtual Timing Mode used when the MODESELECT bit is set to 0b1. See, Virtual IO Timing Modes for details.
  [3:0] GPMC_A3_MUXMODE rw
    0=GPMC_A3; 1=QSPI1_CS2; 2=VIN3A_D19; 3=VOUT3_D19; 4=VIN4A_D3; 6=VIN4B_D3; 7=UART7_TXD; 8=UART5_RTSN; 14=GPIO7_6; 15=DRIVER OFF
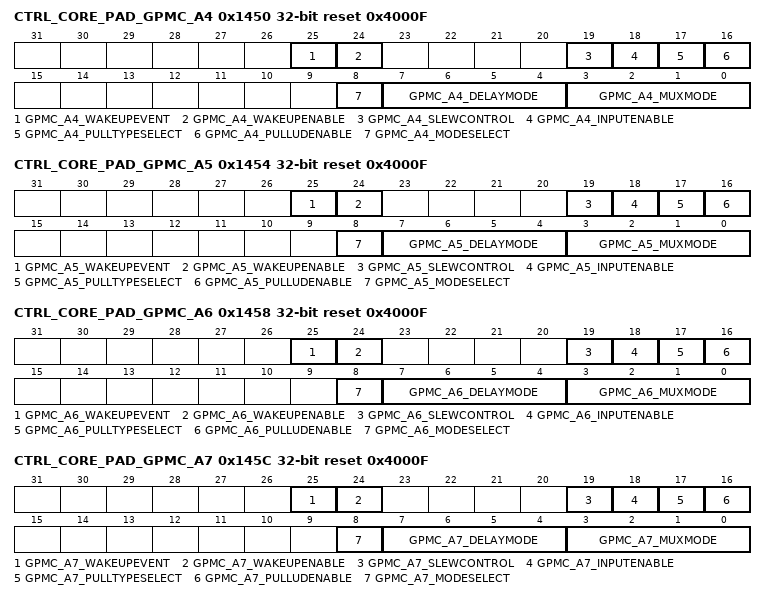
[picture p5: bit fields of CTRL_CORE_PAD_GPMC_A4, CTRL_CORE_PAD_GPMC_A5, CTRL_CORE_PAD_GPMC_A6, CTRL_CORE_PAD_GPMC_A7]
0x1450 CTRL_CORE_PAD_GPMC_A4 reset 0x4000F
  [25] GPMC_A4_WAKEUPEVENT ro
    values as CTRL_CORE_PAD_GPMC_AD0.GPMC_AD0_WAKEUPEVENT
  [24] GPMC_A4_WAKEUPENABLE rw
    0=DISABLE (Wakeup is disabled); 1=ENABLE (Wakeup is enabled)
  [19] GPMC_A4_SLEWCONTROL rw
    values as CTRL_CORE_PAD_GPMC_AD0.GPMC_AD0_SLEWCONTROL
  [18] GPMC_A4_INPUTENABLE rw
    values as CTRL_CORE_PAD_GPMC_AD0.GPMC_AD0_INPUTENABLE
  [17] GPMC_A4_PULLTYPESELECT rw
    values as CTRL_CORE_PAD_GPMC_AD0.GPMC_AD0_PULLTYPESELECT
  [16] GPMC_A4_PULLUDENABLE rw
    values as CTRL_CORE_PAD_GPMC_AD0.GPMC_AD0_PULLUDENABLE
  [8] GPMC_A4_MODESELECT rw — Selects between the Default IO Timing Mode and a Virtual or Manual IO Timing Mode. Refer to the device Data Manual for definition of the required settings for a given mode of operation. When this bit is 0b1, a Virtual IO Timing Mode can be selected via the DELAYMODE field of this register, as described in, Virtual IO Timing Modes. Manual IO Timing Modes are selected via the procedure described in , Manual IO Timing Modes.
    values as CTRL_CORE_PAD_GPMC_AD0.GPMC_AD0_MODESELECT
  [7:4] GPMC_A4_DELAYMODE rw — This bit field selects the Virtual Timing Mode used when the MODESELECT bit is set to 0b1. See, Virtual IO Timing Modes for details.
  [3:0] GPMC_A4_MUXMODE rw
    0=GPMC_A4; 1=QSPI1_CS3; 2=VIN3A_D20; 3=VOUT3_D20; 4=VIN4A_D4; 6=VIN4B_D4; 7=I2C5_SCL; 8=UART6_RXD; 14=GPIO1_26; 15=DRIVER OFF
0x1454 CTRL_CORE_PAD_GPMC_A5 reset 0x4000F
  [25] GPMC_A5_WAKEUPEVENT ro
    values as CTRL_CORE_PAD_GPMC_AD0.GPMC_AD0_WAKEUPEVENT
  [24] GPMC_A5_WAKEUPENABLE rw
    0=DISABLE (Wakeup is disabled); 1=ENABLE (Wakeup is enabled)
  [19] GPMC_A5_SLEWCONTROL rw
    values as CTRL_CORE_PAD_GPMC_AD0.GPMC_AD0_SLEWCONTROL
  [18] GPMC_A5_INPUTENABLE rw
    values as CTRL_CORE_PAD_GPMC_AD0.GPMC_AD0_INPUTENABLE
  [17] GPMC_A5_PULLTYPESELECT rw
    values as CTRL_CORE_PAD_GPMC_AD0.GPMC_AD0_PULLTYPESELECT
  [16] GPMC_A5_PULLUDENABLE rw
    values as CTRL_CORE_PAD_GPMC_AD0.GPMC_AD0_PULLUDENABLE
  [8] GPMC_A5_MODESELECT rw — Selects between the Default IO Timing Mode and a Virtual or Manual IO Timing Mode. Refer to the device Data Manual for definition of the required settings for a given mode of operation. When this bit is 0b1, a Virtual IO Timing Mode can be selected via the DELAYMODE field of this register, as described in, Virtual IO Timing Modes. Manual IO Timing Modes are selected via the procedure described in , Manual IO Timing Modes.
    values as CTRL_CORE_PAD_GPMC_AD0.GPMC_AD0_MODESELECT
  [7:4] GPMC_A5_DELAYMODE rw — This bit field selects the Virtual Timing Mode used when the MODESELECT bit is set to 0b1. See, Virtual IO Timing Modes for details.
  [3:0] GPMC_A5_MUXMODE rw
    0=GPMC_A5; 2=VIN3A_D21; 3=VOUT3_D21; 4=VIN4A_D5; 6=VIN4B_D5; 7=I2C5_SDA; 8=UART6_TXD; 14=GPIO1_27; 15=DRIVER OFF
0x1458 CTRL_CORE_PAD_GPMC_A6 reset 0x4000F
  [25] GPMC_A6_WAKEUPEVENT ro
    values as CTRL_CORE_PAD_GPMC_AD0.GPMC_AD0_WAKEUPEVENT
  [24] GPMC_A6_WAKEUPENABLE rw
    0=DISABLE (Wakeup is disabled); 1=ENABLE (Wakeup is enabled)
  [19] GPMC_A6_SLEWCONTROL rw
    values as CTRL_CORE_PAD_GPMC_AD0.GPMC_AD0_SLEWCONTROL
  [18] GPMC_A6_INPUTENABLE rw
    values as CTRL_CORE_PAD_GPMC_AD0.GPMC_AD0_INPUTENABLE
  [17] GPMC_A6_PULLTYPESELECT rw
    values as CTRL_CORE_PAD_GPMC_AD0.GPMC_AD0_PULLTYPESELECT
  [16] GPMC_A6_PULLUDENABLE rw
    values as CTRL_CORE_PAD_GPMC_AD0.GPMC_AD0_PULLUDENABLE
  [8] GPMC_A6_MODESELECT rw — Selects between the Default IO Timing Mode and a Virtual or Manual IO Timing Mode. Refer to the device Data Manual for definition of the required settings for a given mode of operation. When this bit is 0b1, a Virtual IO Timing Mode can be selected via the DELAYMODE field of this register, as described in, Virtual IO Timing Modes. Manual IO Timing Modes are selected via the procedure described in , Manual IO Timing Modes.
    values as CTRL_CORE_PAD_GPMC_AD0.GPMC_AD0_MODESELECT
  [7:4] GPMC_A6_DELAYMODE rw — This bit field selects the Virtual Timing Mode used when the MODESELECT bit is set to 0b1. See, Virtual IO Timing Modes for details.
  [3:0] GPMC_A6_MUXMODE rw
    0=GPMC_A6; 2=VIN3A_D22; 3=VOUT3_D22; 4=VIN4A_D6; 6=VIN4B_D6; 7=UART8_RXD; 8=UART6_CTSN; 14=GPIO1_28; 15=DRIVER OFF
0x145C CTRL_CORE_PAD_GPMC_A7 reset 0x4000F
  [25] GPMC_A7_WAKEUPEVENT ro
    values as CTRL_CORE_PAD_GPMC_AD0.GPMC_AD0_WAKEUPEVENT
  [24] GPMC_A7_WAKEUPENABLE rw
    0=DISABLE (Wakeup is disabled); 1=ENABLE (Wakeup is enabled)
  [19] GPMC_A7_SLEWCONTROL rw
    values as CTRL_CORE_PAD_GPMC_AD0.GPMC_AD0_SLEWCONTROL
  [18] GPMC_A7_INPUTENABLE rw
    values as CTRL_CORE_PAD_GPMC_AD0.GPMC_AD0_INPUTENABLE
  [17] GPMC_A7_PULLTYPESELECT rw
    values as CTRL_CORE_PAD_GPMC_AD0.GPMC_AD0_PULLTYPESELECT
  [16] GPMC_A7_PULLUDENABLE rw
    values as CTRL_CORE_PAD_GPMC_AD0.GPMC_AD0_PULLUDENABLE
  [8] GPMC_A7_MODESELECT rw — Selects between the Default IO Timing Mode and a Virtual or Manual IO Timing Mode. Refer to the device Data Manual for definition of the required settings for a given mode of operation. When this bit is 0b1, a Virtual IO Timing Mode can be selected via the DELAYMODE field of this register, as described in, Virtual IO Timing Modes. Manual IO Timing Modes are selected via the procedure described in , Manual IO Timing Modes.
    values as CTRL_CORE_PAD_GPMC_AD0.GPMC_AD0_MODESELECT
  [7:4] GPMC_A7_DELAYMODE rw — This bit field selects the Virtual Timing Mode used when the MODESELECT bit is set to 0b1. See, Virtual IO Timing Modes for details.
  [3:0] GPMC_A7_MUXMODE rw
    0=GPMC_A7; 2=VIN3A_D23; 3=VOUT3_D23; 4=VIN4A_D7; 6=VIN4B_D7; 7=UART8_TXD; 8=UART6_RTSN; 14=GPIO1_29; 15=DRIVER OFF
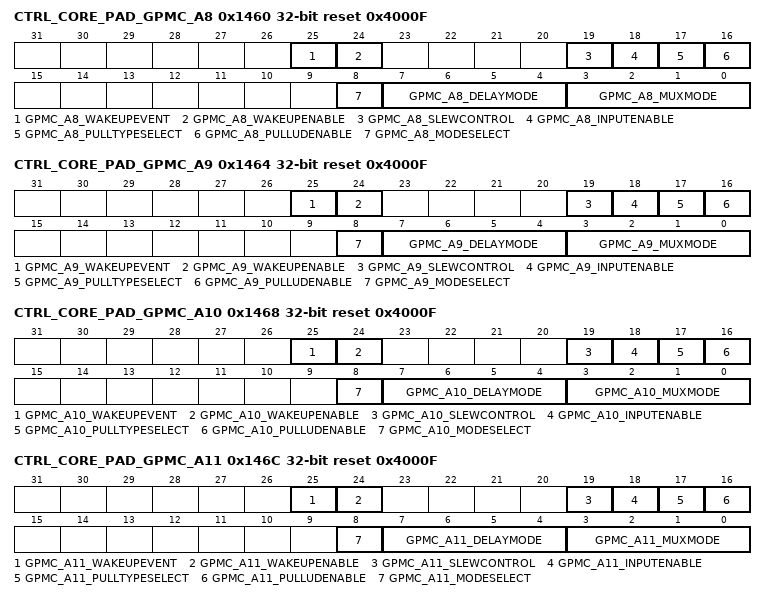
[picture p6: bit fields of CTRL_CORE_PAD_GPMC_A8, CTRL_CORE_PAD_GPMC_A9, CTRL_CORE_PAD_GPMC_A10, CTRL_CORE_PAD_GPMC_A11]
0x1460 CTRL_CORE_PAD_GPMC_A8 reset 0x4000F
  [25] GPMC_A8_WAKEUPEVENT ro
    values as CTRL_CORE_PAD_GPMC_AD0.GPMC_AD0_WAKEUPEVENT
  [24] GPMC_A8_WAKEUPENABLE rw
    0=DISABLE (Wakeup is disabled); 1=ENABLE (Wakeup is enabled)
  [19] GPMC_A8_SLEWCONTROL rw
    values as CTRL_CORE_PAD_GPMC_AD0.GPMC_AD0_SLEWCONTROL
  [18] GPMC_A8_INPUTENABLE rw
    values as CTRL_CORE_PAD_GPMC_AD0.GPMC_AD0_INPUTENABLE
  [17] GPMC_A8_PULLTYPESELECT rw
    values as CTRL_CORE_PAD_GPMC_AD0.GPMC_AD0_PULLTYPESELECT
  [16] GPMC_A8_PULLUDENABLE rw
    values as CTRL_CORE_PAD_GPMC_AD0.GPMC_AD0_PULLUDENABLE
  [8] GPMC_A8_MODESELECT rw — Selects between the Default IO Timing Mode and a Virtual or Manual IO Timing Mode. Refer to the device Data Manual for definition of the required settings for a given mode of operation. When this bit is 0b1, a Virtual IO Timing Mode can be selected via the DELAYMODE field of this register, as described in, Virtual IO Timing Modes. Manual IO Timing Modes are selected via the procedure described in , Manual IO Timing Modes.
    values as CTRL_CORE_PAD_GPMC_AD0.GPMC_AD0_MODESELECT
  [7:4] GPMC_A8_DELAYMODE rw — This bit field selects the Virtual Timing Mode used when the MODESELECT bit is set to 0b1. See, Virtual IO Timing Modes for details.
  [3:0] GPMC_A8_MUXMODE rw
    0=GPMC_A8; 2=VIN3A_HSYNC0; 3=VOUT3_HSYNC; 6=VIN4B_HSYNC1; 7=TIMER12; 8=SPI4_SCLK; 14=GPIO1_30; 15=DRIVER OFF
0x1464 CTRL_CORE_PAD_GPMC_A9 reset 0x4000F
  [25] GPMC_A9_WAKEUPEVENT ro
    values as CTRL_CORE_PAD_GPMC_AD0.GPMC_AD0_WAKEUPEVENT
  [24] GPMC_A9_WAKEUPENABLE rw
    0=DISABLE (Wakeup is disabled); 1=ENABLE (Wakeup is enabled)
  [19] GPMC_A9_SLEWCONTROL rw
    values as CTRL_CORE_PAD_GPMC_AD0.GPMC_AD0_SLEWCONTROL
  [18] GPMC_A9_INPUTENABLE rw
    values as CTRL_CORE_PAD_GPMC_AD0.GPMC_AD0_INPUTENABLE
  [17] GPMC_A9_PULLTYPESELECT rw
    values as CTRL_CORE_PAD_GPMC_AD0.GPMC_AD0_PULLTYPESELECT
  [16] GPMC_A9_PULLUDENABLE rw
    values as CTRL_CORE_PAD_GPMC_AD0.GPMC_AD0_PULLUDENABLE
  [8] GPMC_A9_MODESELECT rw — Selects between the Default IO Timing Mode and a Virtual or Manual IO Timing Mode. Refer to the device Data Manual for definition of the required settings for a given mode of operation. When this bit is 0b1, a Virtual IO Timing Mode can be selected via the DELAYMODE field of this register, as described in, Virtual IO Timing Modes. Manual IO Timing Modes are selected via the procedure described in , Manual IO Timing Modes.
    values as CTRL_CORE_PAD_GPMC_AD0.GPMC_AD0_MODESELECT
  [7:4] GPMC_A9_DELAYMODE rw — This bit field selects the Virtual Timing Mode used when the MODESELECT bit is set to 0b1. See, Virtual IO Timing Modes for details.
  [3:0] GPMC_A9_MUXMODE rw
    0=GPMC_A9; 2=VIN3A_VSYNC0; 3=VOUT3_VSYNC; 6=VIN4B_VSYNC1; 7=TIMER11; 8=SPI4_D1; 14=GPIO1_31; 15=DRIVER OFF
0x1468 CTRL_CORE_PAD_GPMC_A10 reset 0x4000F
  [25] GPMC_A10_WAKEUPEVENT ro
    values as CTRL_CORE_PAD_GPMC_AD0.GPMC_AD0_WAKEUPEVENT
  [24] GPMC_A10_WAKEUPENABLE rw
    0=DISABLE (Wakeup is disabled); 1=ENABLE (Wakeup is enabled)
  [19] GPMC_A10_SLEWCONTROL rw
    values as CTRL_CORE_PAD_GPMC_AD0.GPMC_AD0_SLEWCONTROL
  [18] GPMC_A10_INPUTENABLE rw
    values as CTRL_CORE_PAD_GPMC_AD0.GPMC_AD0_INPUTENABLE
  [17] GPMC_A10_PULLTYPESELECT rw
    values as CTRL_CORE_PAD_GPMC_AD0.GPMC_AD0_PULLTYPESELECT
  [16] GPMC_A10_PULLUDENABLE rw
    values as CTRL_CORE_PAD_GPMC_AD0.GPMC_AD0_PULLUDENABLE
  [8] GPMC_A10_MODESELECT rw — Selects between the Default IO Timing Mode and a Virtual or Manual IO Timing Mode. Refer to the device Data Manual for definition of the required settings for a given mode of operation. When this bit is 0b1, a Virtual IO Timing Mode can be selected via the DELAYMODE field of this register, as described in, Virtual IO Timing Modes. Manual IO Timing Modes are selected via the procedure described in , Manual IO Timing Modes.
    values as CTRL_CORE_PAD_GPMC_AD0.GPMC_AD0_MODESELECT
  [7:4] GPMC_A10_DELAYMODE rw — This bit field selects the Virtual Timing Mode used when the MODESELECT bit is set to 0b1. See, Virtual IO Timing Modes for details.
  [3:0] GPMC_A10_MUXMODE rw
    0=GPMC_A10; 2=VIN3A_DE0; 3=VOUT3_DE; 6=VIN4B_CLK1; 7=TIMER10; 8=SPI4_D0; 14=GPIO2_0; 15=DRIVER OFF
0x146C CTRL_CORE_PAD_GPMC_A11 reset 0x4000F
  [25] GPMC_A11_WAKEUPEVENT ro
    values as CTRL_CORE_PAD_GPMC_AD0.GPMC_AD0_WAKEUPEVENT
  [24] GPMC_A11_WAKEUPENABLE rw
    0=DISABLE (Wakeup is disabled); 1=ENABLE (Wakeup is enabled)
  [19] GPMC_A11_SLEWCONTROL rw
    values as CTRL_CORE_PAD_GPMC_AD0.GPMC_AD0_SLEWCONTROL
  [18] GPMC_A11_INPUTENABLE rw
    values as CTRL_CORE_PAD_GPMC_AD0.GPMC_AD0_INPUTENABLE
  [17] GPMC_A11_PULLTYPESELECT rw
    values as CTRL_CORE_PAD_GPMC_AD0.GPMC_AD0_PULLTYPESELECT
  [16] GPMC_A11_PULLUDENABLE rw
    values as CTRL_CORE_PAD_GPMC_AD0.GPMC_AD0_PULLUDENABLE
  [8] GPMC_A11_MODESELECT rw — Selects between the Default IO Timing Mode and a Virtual or Manual IO Timing Mode. Refer to the device Data Manual for definition of the required settings for a given mode of operation. When this bit is 0b1, a Virtual IO Timing Mode can be selected via the DELAYMODE field of this register, as described in, Virtual IO Timing Modes. Manual IO Timing Modes are selected via the procedure described in , Manual IO Timing Modes.
    values as CTRL_CORE_PAD_GPMC_AD0.GPMC_AD0_MODESELECT
  [7:4] GPMC_A11_DELAYMODE rw — This bit field selects the Virtual Timing Mode used when the MODESELECT bit is set to 0b1. See, Virtual IO Timing Modes for details.
  [3:0] GPMC_A11_MUXMODE rw
    0=GPMC_A11; 2=VIN3A_FLD0; 3=VOUT3_FLD; 4=VIN4A_FLD0; 6=VIN4B_DE1; 7=TIMER9; 8=SPI4_CS0; 14=GPIO2_1; 15=DRIVER OFF
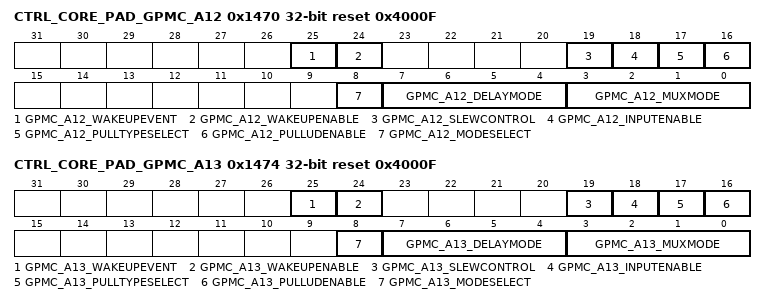
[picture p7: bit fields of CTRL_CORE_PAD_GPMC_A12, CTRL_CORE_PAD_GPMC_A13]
0x1470 CTRL_CORE_PAD_GPMC_A12 reset 0x4000F
  [25] GPMC_A12_WAKEUPEVENT ro
    values as CTRL_CORE_PAD_GPMC_AD0.GPMC_AD0_WAKEUPEVENT
  [24] GPMC_A12_WAKEUPENABLE rw
    0=DISABLE (Wakeup is disabled); 1=ENABLE (Wakeup is enabled)
  [19] GPMC_A12_SLEWCONTROL rw
    values as CTRL_CORE_PAD_GPMC_AD0.GPMC_AD0_SLEWCONTROL
  [18] GPMC_A12_INPUTENABLE rw
    values as CTRL_CORE_PAD_GPMC_AD0.GPMC_AD0_INPUTENABLE
  [17] GPMC_A12_PULLTYPESELECT rw
    values as CTRL_CORE_PAD_GPMC_AD0.GPMC_AD0_PULLTYPESELECT
  [16] GPMC_A12_PULLUDENABLE rw
    values as CTRL_CORE_PAD_GPMC_AD0.GPMC_AD0_PULLUDENABLE
  [8] GPMC_A12_MODESELECT rw — Selects between the Default IO Timing Mode and a Virtual or Manual IO Timing Mode. Refer to the device Data Manual for definition of the required settings for a given mode of operation. When this bit is 0b1, a Virtual IO Timing Mode can be selected via the DELAYMODE field of this register, as described in, Virtual IO Timing Modes. Manual IO Timing Modes are selected via the procedure described in , Manual IO Timing Modes.
    values as CTRL_CORE_PAD_GPMC_AD0.GPMC_AD0_MODESELECT
  [7:4] GPMC_A12_DELAYMODE rw — This bit field selects the Virtual Timing Mode used when the MODESELECT bit is set to 0b1. See, Virtual IO Timing Modes for details.
  [3:0] GPMC_A12_MUXMODE rw
    0=GPMC_A12; 4=VIN4A_CLK0; 5=GPMC_A0; 6=VIN4B_FLD1; 7=TIMER8; 8=SPI4_CS1; 9=DMA_EVT1; 14=GPIO2_2; 15=DRIVER OFF
0x1474 CTRL_CORE_PAD_GPMC_A13 reset 0x4000F
  [25] GPMC_A13_WAKEUPEVENT ro
    values as CTRL_CORE_PAD_GPMC_AD0.GPMC_AD0_WAKEUPEVENT
  [24] GPMC_A13_WAKEUPENABLE rw
    0=DISABLE (Wakeup is disabled); 1=ENABLE (Wakeup is enabled)
  [19] GPMC_A13_SLEWCONTROL rw
    values as CTRL_CORE_PAD_GPMC_AD0.GPMC_AD0_SLEWCONTROL
  [18] GPMC_A13_INPUTENABLE rw
    values as CTRL_CORE_PAD_GPMC_AD0.GPMC_AD0_INPUTENABLE
  [17] GPMC_A13_PULLTYPESELECT rw
    values as CTRL_CORE_PAD_GPMC_AD0.GPMC_AD0_PULLTYPESELECT
  [16] GPMC_A13_PULLUDENABLE rw
    values as CTRL_CORE_PAD_GPMC_AD0.GPMC_AD0_PULLUDENABLE
  [8] GPMC_A13_MODESELECT rw — Selects between the Default IO Timing Mode and a Virtual or Manual IO Timing Mode. Refer to the device Data Manual for definition of the required settings for a given mode of operation. When this bit is 0b1, a Virtual IO Timing Mode can be selected via the DELAYMODE field of this register, as described in, Virtual IO Timing Modes. Manual IO Timing Modes are selected via the procedure described in , Manual IO Timing Modes.
    values as CTRL_CORE_PAD_GPMC_AD0.GPMC_AD0_MODESELECT
  [7:4] GPMC_A13_DELAYMODE rw — This bit field selects the Virtual Timing Mode used when the MODESELECT bit is set to 0b1. See, Virtual IO Timing Modes for details.
  [3:0] GPMC_A13_MUXMODE rw
    0=GPMC_A13; 1=QSPI1_RTCLK; 4=VIN4A_HSYNC0; 7=TIMER7; 8=SPI4_CS2; 9=DMA_EVT2; 14=GPIO2_3; 15=DRIVER OFF
